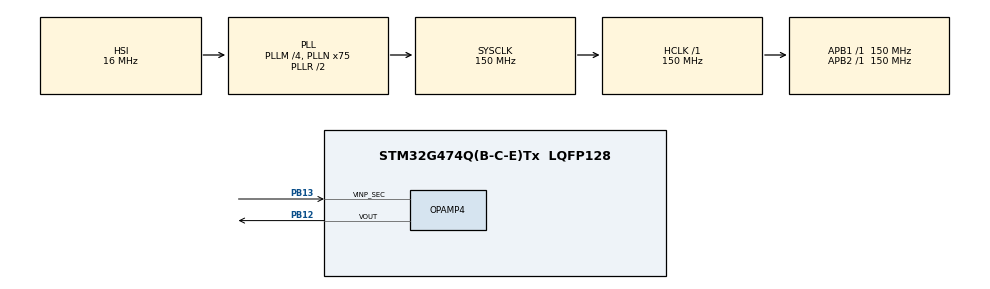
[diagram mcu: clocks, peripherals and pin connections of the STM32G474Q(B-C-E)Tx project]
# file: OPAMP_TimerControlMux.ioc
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DAC4.DAC_OutputBuffer-DAC_OUT1_Int=DAC_OUTPUTBUFFER_DISABLE
DAC4.DAC_Trigger-DAC_OUT1_ExtAndInt=DAC_TRIGGER_T2_TRGO
DAC4.DAC_Trigger_OUT1-DAC_OUT1_Int=DAC_TRIGGER_T2_TRGO
DAC4.TriangleAmplitude_OUT1-DAC_OUT1_Int=DAC_TRIANGLEAMPLITUDE_4095
DAC4.WaveGeneration_OUT1-DAC_OUT1_Int=TriangleWaveGeneration
Mcu.Family=STM32G4
Mcu.Name=STM32G474Q(B-C-E)Tx
Mcu.Package=LQFP128
NVIC.PriorityGroup=NVIC_PRIORITYGROUP_4
OPAMP4.PowerMode=OPAMP_POWERMODE_NORMAL
PB12.Mode=Follower-DAC_OUT2-INP
PB12.Signal=OPAMP4_VOUT
PB13.Mode=Switching On Non Inverting Inputs Using Different Pins
PB13.Signal=OPAMP4_VINP_SEC
ProjectManager.HeapSize=0x200
ProjectManager.StackSize=0x400
ProjectManager.TargetToolchain=EWARM V8.32
RCC.ADC12Freq_Value=150000000
RCC.ADC345Freq_Value=150000000
RCC.AHBFreq_Value=150000000
RCC.APB1Freq_Value=150000000
RCC.APB1TimFreq_Value=150000000
RCC.APB2Freq_Value=150000000
RCC.APB2TimFreq_Value=150000000
RCC.CortexFreq_Value=150000000
RCC.EXTERNAL_CLOCK_VALUE=12288000
RCC.HCLKFreq_Value=150000000
RCC.HSE_VALUE=24000000
RCC.HSI48_VALUE=48000000
RCC.HSI_VALUE=16000000
RCC.LSE_VALUE=32768
RCC.PLLM=RCC_PLLM_DIV4
RCC.PLLN=75
RCC.SYSCLKFreq_VALUE=150000000
RCC.SYSCLKSource=RCC_SYSCLKSOURCE_PLLCLK
RCC.USBFreq_Value=150000000
RCC.VCOOutputFreq_Value=300000000
TIM1.AutoReloadPreload=TIM_AUTORELOAD_PRELOAD_DISABLE
TIM1.AutomaticOutput=TIM_AUTOMATICOUTPUT_DISABLE
TIM1.Break2Filter=0
TIM1.Break2Polarity=TIM_BREAK2POLARITY_HIGH
TIM1.Break2State=TIM_BREAK2_DISABLE
TIM1.BreakFilter=0
TIM1.BreakPolarity=TIM_BREAKPOLARITY_HIGH
TIM1.BreakState=TIM_BREAK_DISABLE
TIM1.Channel-Output\ Compare6\ No\ Output=TIM_CHANNEL_6
TIM1.ClearInputSource=TIM_CLEARINPUTSOURCE_NONE
TIM1.ClockDivision=TIM_CLOCKDIVISION_DIV1
TIM1.CounterMode=TIM_COUNTERMODE_UP
TIM1.Dithering=Disable
TIM1.LockLevel=TIM_LOCKLEVEL_OFF
TIM1.OCIdleState_6=TIM_OCIDLESTATE_RESET
TIM1.OCMode_6=TIM_OCMODE_TOGGLE
TIM1.OCPolarity_6=TIM_OCPOLARITY_HIGH
TIM1.OffStateIDLEMode=TIM_OSSI_DISABLE
TIM1.PeriodNoDither=150
TIM1.Prescaler=4096*4
TIM1.PulseNoDither_6=100
TIM1.RepetitionCounter=0
TIM1.SourceBRK2COMP1=TIM_BREAKINPUTSOURCE_DISABLE
TIM1.SourceBRK2COMP2=TIM_BREAKINPUTSOURCE_DISABLE
TIM1.SourceBRK2COMP3=TIM_BREAKINPUTSOURCE_DISABLE
TIM1.SourceBRK2COMP4=TIM_BREAKINPUTSOURCE_DISABLE
TIM1.SourceBRK2COMP5=TIM_BREAKINPUTSOURCE_DISABLE
TIM1.SourceBRK2COMP6=TIM_BREAKINPUTSOURCE_DISABLE
TIM1.SourceBRK2COMP7=TIM_BREAKINPUTSOURCE_DISABLE
TIM1.SourceBRK2DigInput=TIM_BREAKINPUTSOURCE_DISABLE
TIM1.SourceBRKCOMP1=TIM_BREAKINPUTSOURCE_DISABLE
TIM1.SourceBRKCOMP2=TIM_BREAKINPUTSOURCE_DISABLE
TIM1.SourceBRKCOMP3=TIM_BREAKINPUTSOURCE_DISABLE
TIM1.SourceBRKCOMP4=TIM_BREAKINPUTSOURCE_DISABLE
TIM1.SourceBRKCOMP5=TIM_BREAKINPUTSOURCE_DISABLE
TIM1.SourceBRKCOMP6=TIM_BREAKINPUTSOURCE_DISABLE
TIM1.SourceBRKCOMP7=TIM_BREAKINPUTSOURCE_DISABLE
TIM1.SourceBRKDigInput=TIM_BREAKINPUTSOURCE_DISABLE
TIM1.TIM_MasterOutputTrigger=TIM_TRGO_RESET
TIM1.TIM_MasterOutputTrigger2=TIM_TRGO2_RESET
TIM1.TIM_MasterSlaveMode=TIM_MASTERSLAVEMODE_DISABLE
TIM2.AutoReloadPreload=TIM_AUTORELOAD_PRELOAD_DISABLE
TIM2.ClockDivision=TIM_CLOCKDIVISION_DIV1
TIM2.CounterMode=TIM_COUNTERMODE_UP
TIM2.Dithering=Disable
TIM2.PeriodNoDither=150
TIM2.Prescaler=0
TIM2.TIM_MasterOutputTrigger=TIM_TRGO_UPDATE
TIM2.TIM_MasterSlaveMode=TIM_MASTERSLAVEMODE_DISABLE
VP_DAC4_VS_DACI1.Mode=DAC_OUT1_Int
VP_OPAMP4_VIN_MUX.Mode=Timer Controlled Mux Mode
VP_SYS_VS_DBSignals.Mode=DisableDeadBatterySignals
VP_TIM1_VS_ClockSourceINT.Mode=Internal
VP_TIM1_VS_no_output6.Mode=Output Compare6 No Output
VP_TIM2_VS_ClockSourceINT.Mode=Internal
board=custom

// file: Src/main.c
/* USER CODE BEGIN Header */
/**
  ******************************************************************************
  * @file    Examples/OPAMP/OPAMP_TimerControlMux/Src/main.c
  * @author  MCD Application Team
  * @brief   This example shows how to use the timer controlled multiplexer mode
  *          of the OPAMP
  ******************************************************************************
  * @attention
  *
  * Copyright (c) 2019 STMicroelectronics.
  * All rights reserved.
  *
  * This software is licensed under terms that can be found in the LICENSE file
  * in the root directory of this software component.
  * If no LICENSE file comes with this software, it is provided AS-IS.
  *
  ******************************************************************************
  */
/* USER CODE END Header */
#include "main.h"

/* USER CODE BEGIN Includes */
#include "stm32g474e_eval.h"
/* USER CODE END Includes */

DAC_HandleTypeDef hdac4;

OPAMP_HandleTypeDef hopamp4;

TIM_HandleTypeDef htim1;
TIM_HandleTypeDef htim2;

/* USER CODE BEGIN PV */
/* Private variables ---------------------------------------------------------*/
/* USER CODE END PV */

void SystemClock_Config(void);
static void MX_GPIO_Init(void);
static void MX_DAC4_Init(void);
static void MX_OPAMP4_Init(void);
static void MX_TIM1_Init(void);
static void MX_TIM2_Init(void);
/* USER CODE BEGIN PFP */
/* Private function prototypes -----------------------------------------------*/
/* USER CODE END PFP */

int main(void)
{

  /* MCU Configuration--------------------------------------------------------*/

  /* Reset of all peripherals, Initializes the Flash interface and the Systick. */
  HAL_Init();

  /* Configure the system clock */
  SystemClock_Config();

  /* Initialize all configured peripherals */
  MX_GPIO_Init();
  MX_DAC4_Init();
  MX_OPAMP4_Init();
  MX_TIM1_Init();
  MX_TIM2_Init();
  /* USER CODE BEGIN 2 */
  /* Initialize LED on board */
  BSP_LED_Init(LED1);

  /* USER CODE END 2 */

  /* Infinite loop */
  /* USER CODE BEGIN WHILE */
  /*##- Enable DAC Channel and wave generation #############################*/
  if(HAL_OK != HAL_DAC_Start(&hdac4, DAC_CHANNEL_1))
  {
    /* Start DMA Error */
    Error_Handler();
  }
  /*##- Enable TIM trigger for wave generation #############################*/
  if(HAL_OK != HAL_TIM_Base_Start(&htim2))
  {
    Error_Handler();
  }

  /*##- Start OPAMP    #####################################################*/
  /* Enable OPAMP */
  if(HAL_OK != HAL_OPAMP_Start(&hopamp4))
  {
    Error_Handler();
  }

  /*##- Enable TIM trigger for OPAMP multiplexer ###########################*/
  if(HAL_OK != HAL_TIM_OC_Start(&htim1, TIM_CHANNEL_6))
  {
    Error_Handler();
  }

  BSP_LED_On(LED1);
  while (1)
  {
  }
    /* USER CODE END WHILE */

}

void SystemClock_Config(void)
{
  RCC_OscInitTypeDef RCC_OscInitStruct = {0};
  RCC_ClkInitTypeDef RCC_ClkInitStruct = {0};

  /** Configure the main internal regulator output voltage
  */
  HAL_PWREx_ControlVoltageScaling(PWR_REGULATOR_VOLTAGE_SCALE1);

  /** Initializes the RCC Oscillators according to the specified parameters
  * in the RCC_OscInitTypeDef structure.
  */
  RCC_OscInitStruct.OscillatorType = RCC_OSCILLATORTYPE_HSI;
  RCC_OscInitStruct.HSIState = RCC_HSI_ON;
  RCC_OscInitStruct.HSICalibrationValue = RCC_HSICALIBRATION_DEFAULT;
  RCC_OscInitStruct.PLL.PLLState = RCC_PLL_ON;
  RCC_OscInitStruct.PLL.PLLSource = RCC_PLLSOURCE_HSI;
  RCC_OscInitStruct.PLL.PLLM = RCC_PLLM_DIV4;
  RCC_OscInitStruct.PLL.PLLN = 75;
  RCC_OscInitStruct.PLL.PLLP = RCC_PLLP_DIV2;
  RCC_OscInitStruct.PLL.PLLQ = RCC_PLLQ_DIV2;
  RCC_OscInitStruct.PLL.PLLR = RCC_PLLR_DIV2;
  if (HAL_RCC_OscConfig(&RCC_OscInitStruct) != HAL_OK)
  {
    Error_Handler();
  }

  /** Initializes the CPU, AHB and APB buses clocks
  */
  RCC_ClkInitStruct.ClockType = RCC_CLOCKTYPE_HCLK|RCC_CLOCKTYPE_SYSCLK
                              |RCC_CLOCKTYPE_PCLK1|RCC_CLOCKTYPE_PCLK2;
  RCC_ClkInitStruct.SYSCLKSource = RCC_SYSCLKSOURCE_PLLCLK;
  RCC_ClkInitStruct.AHBCLKDivider = RCC_SYSCLK_DIV1;
  RCC_ClkInitStruct.APB1CLKDivider = RCC_HCLK_DIV1;
  RCC_ClkInitStruct.APB2CLKDivider = RCC_HCLK_DIV1;

  if (HAL_RCC_ClockConfig(&RCC_ClkInitStruct, FLASH_LATENCY_4) != HAL_OK)
  {
    Error_Handler();
  }
}

static void MX_DAC4_Init(void)
{

  DAC_ChannelConfTypeDef sConfig = {0};

  /** DAC Initialization
  */
  hdac4.Instance = DAC4;
  if (HAL_DAC_Init(&hdac4) != HAL_OK)
  {
    Error_Handler();
  }

  /** DAC channel OUT1 config
  */
  sConfig.DAC_HighFrequency = DAC_HIGH_FREQUENCY_INTERFACE_MODE_AUTOMATIC;
  sConfig.DAC_DMADoubleDataMode = DISABLE;
  sConfig.DAC_SignedFormat = DISABLE;
  sConfig.DAC_SampleAndHold = DAC_SAMPLEANDHOLD_DISABLE;
  sConfig.DAC_Trigger = DAC_TRIGGER_T2_TRGO;
  sConfig.DAC_Trigger2 = DAC_TRIGGER_NONE;
  sConfig.DAC_OutputBuffer = DAC_OUTPUTBUFFER_DISABLE;
  sConfig.DAC_ConnectOnChipPeripheral = DAC_CHIPCONNECT_INTERNAL;
  sConfig.DAC_UserTrimming = DAC_TRIMMING_FACTORY;
  if (HAL_DAC_ConfigChannel(&hdac4, &sConfig, DAC_CHANNEL_1) != HAL_OK)
  {
    Error_Handler();
  }

  /** Configure Triangle wave generation on DAC OUT1
  */
  if (HAL_DACEx_TriangleWaveGenerate(&hdac4, DAC_CHANNEL_1, DAC_TRIANGLEAMPLITUDE_4095) != HAL_OK)
  {
    Error_Handler();
  }

}

static void MX_OPAMP4_Init(void)
{

  hopamp4.Instance = OPAMP4;
  hopamp4.Init.PowerMode = OPAMP_POWERMODE_NORMAL;
  hopamp4.Init.Mode = OPAMP_FOLLOWER_MODE;
  hopamp4.Init.NonInvertingInput = OPAMP_NONINVERTINGINPUT_DAC;
  hopamp4.Init.InternalOutput = DISABLE;
  hopamp4.Init.TimerControlledMuxmode = OPAMP_TIMERCONTROLLEDMUXMODE_TIM1_CH6;
  hopamp4.Init.NonInvertingInputSecondary = OPAMP_SEC_NONINVERTINGINPUT_IO0;
  hopamp4.Init.UserTrimming = OPAMP_TRIMMING_FACTORY;
  if (HAL_OPAMP_Init(&hopamp4) != HAL_OK)
  {
    Error_Handler();
  }

}

static void MX_TIM1_Init(void)
{

  TIM_ClockConfigTypeDef sClockSourceConfig = {0};
  TIM_MasterConfigTypeDef sMasterConfig = {0};
  TIM_OC_InitTypeDef sConfigOC = {0};
  TIM_BreakDeadTimeConfigTypeDef sBreakDeadTimeConfig = {0};

  htim1.Instance = TIM1;
  htim1.Init.Prescaler = 4096*4;
  htim1.Init.CounterMode = TIM_COUNTERMODE_UP;
  htim1.Init.Period = 150;
  htim1.Init.ClockDivision = TIM_CLOCKDIVISION_DIV1;
  htim1.Init.RepetitionCounter = 0;
  htim1.Init.AutoReloadPreload = TIM_AUTORELOAD_PRELOAD_DISABLE;
  if (HAL_TIM_Base_Init(&htim1) != HAL_OK)
  {
    Error_Handler();
  }
  sClockSourceConfig.ClockSource = TIM_CLOCKSOURCE_INTERNAL;
  if (HAL_TIM_ConfigClockSource(&htim1, &sClockSourceConfig) != HAL_OK)
  {
    Error_Handler();
  }
  if (HAL_TIM_OC_Init(&htim1) != HAL_OK)
  {
    Error_Handler();
  }
  sMasterConfig.MasterOutputTrigger = TIM_TRGO_RESET;
  sMasterConfig.MasterOutputTrigger2 = TIM_TRGO2_RESET;
  sMasterConfig.MasterSlaveMode = TIM_MASTERSLAVEMODE_DISABLE;
  if (HAL_TIMEx_MasterConfigSynchronization(&htim1, &sMasterConfig) != HAL_OK)
  {
    Error_Handler();
  }
  sConfigOC.OCMode = TIM_OCMODE_TOGGLE;
  sConfigOC.Pulse = 100;
  sConfigOC.OCPolarity = TIM_OCPOLARITY_HIGH;
  sConfigOC.OCFastMode = TIM_OCFAST_DISABLE;
  sConfigOC.OCIdleState = TIM_OCIDLESTATE_RESET;
  if (HAL_TIM_OC_ConfigChannel(&htim1, &sConfigOC, TIM_CHANNEL_6) != HAL_OK)
  {
    Error_Handler();
  }
  sBreakDeadTimeConfig.OffStateRunMode = TIM_OSSR_DISABLE;
  sBreakDeadTimeConfig.OffStateIDLEMode = TIM_OSSI_DISABLE;
  sBreakDeadTimeConfig.LockLevel = TIM_LOCKLEVEL_OFF;
  sBreakDeadTimeConfig.DeadTime = 0;
  sBreakDeadTimeConfig.BreakState = TIM_BREAK_DISABLE;
  sBreakDeadTimeConfig.BreakPolarity = TIM_BREAKPOLARITY_HIGH;
  sBreakDeadTimeConfig.BreakFilter = 0;
  sBreakDeadTimeConfig.BreakAFMode = TIM_BREAK_AFMODE_INPUT;
  sBreakDeadTimeConfig.Break2State = TIM_BREAK2_DISABLE;
  sBreakDeadTimeConfig.Break2Polarity = TIM_BREAK2POLARITY_HIGH;
  sBreakDeadTimeConfig.Break2Filter = 0;
  sBreakDeadTimeConfig.Break2AFMode = TIM_BREAK_AFMODE_INPUT;
  sBreakDeadTimeConfig.AutomaticOutput = TIM_AUTOMATICOUTPUT_DISABLE;
  if (HAL_TIMEx_ConfigBreakDeadTime(&htim1, &sBreakDeadTimeConfig) != HAL_OK)
  {
    Error_Handler();
  }

}

static void MX_TIM2_Init(void)
{

  TIM_ClockConfigTypeDef sClockSourceConfig = {0};
  TIM_MasterConfigTypeDef sMasterConfig = {0};

  htim2.Instance = TIM2;
  htim2.Init.Prescaler = 0;
  htim2.Init.CounterMode = TIM_COUNTERMODE_UP;
  htim2.Init.Period = 150;
  htim2.Init.ClockDivision = TIM_CLOCKDIVISION_DIV1;
  htim2.Init.AutoReloadPreload = TIM_AUTORELOAD_PRELOAD_DISABLE;
  if (HAL_TIM_Base_Init(&htim2) != HAL_OK)
  {
    Error_Handler();
  }
  sClockSourceConfig.ClockSource = TIM_CLOCKSOURCE_INTERNAL;
  if (HAL_TIM_ConfigClockSource(&htim2, &sClockSourceConfig) != HAL_OK)
  {
    Error_Handler();
  }
  sMasterConfig.MasterOutputTrigger = TIM_TRGO_UPDATE;
  sMasterConfig.MasterSlaveMode = TIM_MASTERSLAVEMODE_DISABLE;
  if (HAL_TIMEx_MasterConfigSynchronization(&htim2, &sMasterConfig) != HAL_OK)
  {
    Error_Handler();
  }

}

static void MX_GPIO_Init(void)
{

  /* GPIO Ports Clock Enable */
  __HAL_RCC_GPIOB_CLK_ENABLE();

}

void Error_Handler(void)
{
  /* USER CODE BEGIN Error_Handler_Debug */
  /* User can add his own implementation to report the HAL error return state */

  while(1)
  {
    /* Toggle LED1 */
    BSP_LED_Toggle(LED1);
    HAL_Delay(1000);
  }
  /* USER CODE END Error_Handler_Debug */
}

#ifdef  USE_FULL_ASSERT
/**
  * @brief  Reports the name of the source file and the source line number
  *         where the assert_param error has occurred.
  * @param  file: pointer to the source file name
  * @param  line: assert_param error line source number
  * @retval None
  */
void assert_failed(uint8_t *file, uint32_t line)
{
  /* USER CODE BEGIN 6 */
  /* User can add his own implementation to report the file name and line number,
    ex: printf("Wrong parameters value: file %s on line %d\r\n", file, line) */
  Error_Handler();
  /* USER CODE END 6 */
}
#endif /* USE_FULL_ASSERT */
